# M4KN register map
File version: 0.1
Registers are 32-bit, read-write, reset 0x0 unless marked. A register's access mark holds for its fields unless they carry their own. Offsets are from the block's base; [hi:lo] are bit positions; {n}, {i} and the like mark numbered series.

## PK — Port K
Base 0x400E0900
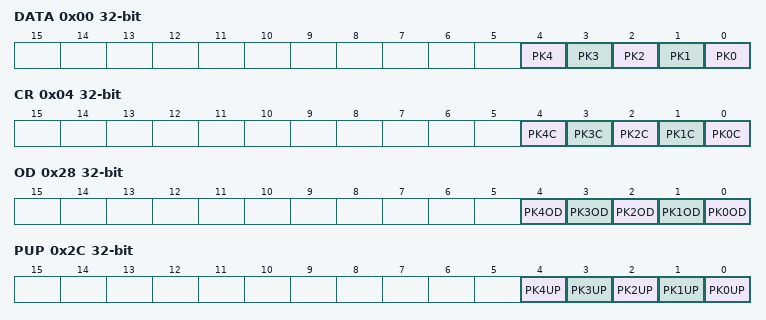
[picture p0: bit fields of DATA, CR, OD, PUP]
0x00 DATA — Port K Data Register
  [n] PK{n} (n=0..4)
0x04 CR — Port K Output Control Register
  [n] PK{n}C (n=0..4)
0x28 OD — Port K Open Drain Control Register
  [n] PK{n}OD (n=0..4)
0x2C PUP — Port K Pull-up Control Register
  [n] PK{n}UP (n=0..4)
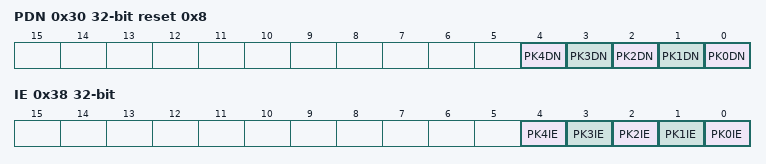
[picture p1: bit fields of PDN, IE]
0x30 PDN reset 0x8 — Port K Pull-down Control Register
  [n] PK{n}DN (n=0..4)
0x38 IE — Port K Input Control Register
  [n] PK{n}IE (n=0..4)

## PL — Port L
Base 0x400E0A00
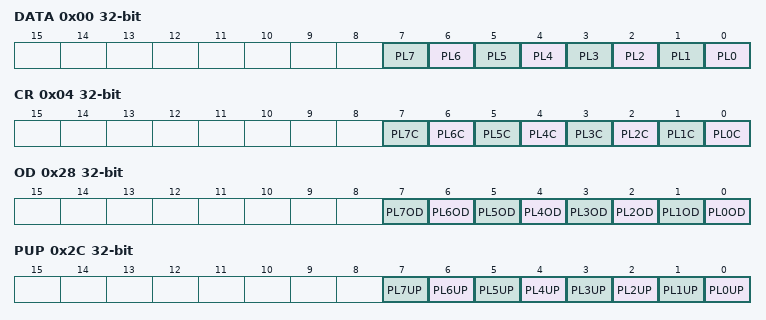
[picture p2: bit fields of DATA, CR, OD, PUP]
0x00 DATA — Port L Data Register
  [n] PL{n} (n=0..7)
0x04 CR — Port L Output Control Register
  [n] PL{n}C (n=0..7)
0x28 OD — Port L Open Drain Control Register
  [n] PL{n}OD (n=0..7)
0x2C PUP — Port L Pull-up Control Register
  [n] PL{n}UP (n=0..7)
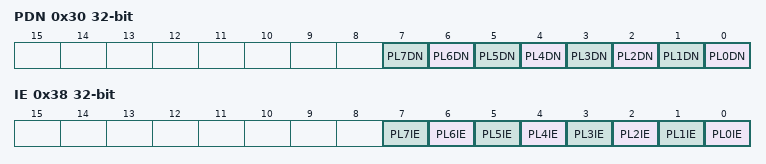
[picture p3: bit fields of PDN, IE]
0x30 PDN — Port L Pull-down Control Register
  [n] PL{n}DN (n=0..7)
0x38 IE — Port L Input Control Register
  [n] PL{n}IE (n=0..7)

## PM — Port M
Base 0x400E0B00
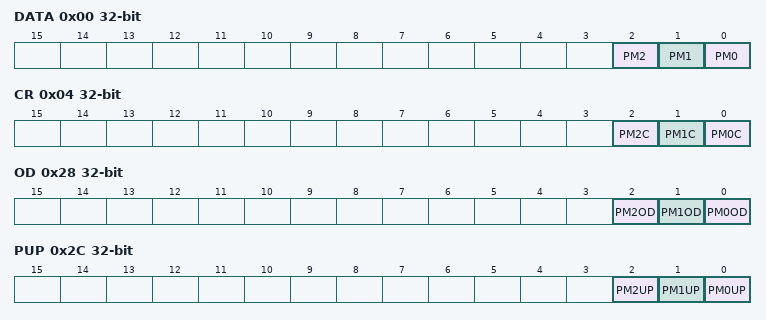
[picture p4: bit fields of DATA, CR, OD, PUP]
0x00 DATA — Port M Data Register
  [2] PM2, [1] PM1, [0] PM0
0x04 CR — Port M Output Control Register
  [2] PM2C, [1] PM1C, [0] PM0C
0x28 OD — Port M Open Drain Control Register
  [2] PM2OD, [1] PM1OD, [0] PM0OD
0x2C PUP — Port M Pull-up Control Register
  [2] PM2UP, [1] PM1UP, [0] PM0UP
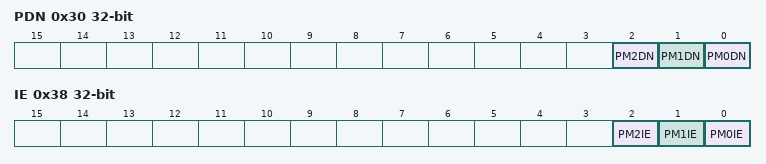
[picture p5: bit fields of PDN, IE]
0x30 PDN — Port M Pull-down Control Register
  [2] PM2DN, [1] PM1DN, [0] PM0DN
0x38 IE — Port M Input Control Register
  [2] PM2IE, [1] PM1IE, [0] PM0IE

## PN — Port N
Base 0x400E0C00
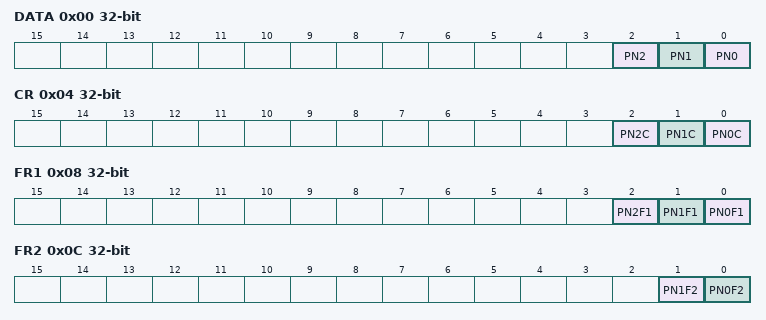
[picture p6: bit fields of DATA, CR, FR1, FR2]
0x00 DATA — Port N Data Register
  [2] PN2, [1] PN1, [0] PN0
0x04 CR — Port N Output Control Register
  [2] PN2C, [1] PN1C, [0] PN0C
0x08 FR1 — Port N Function Register 1
  [2] PN2F1, [1] PN1F1, [0] PN0F1
0x0C FR2 — Port N Function Register 2
  [1] PN1F2, [0] PN0F2
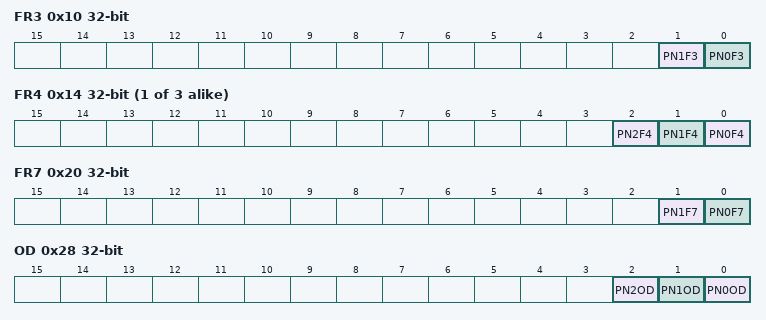
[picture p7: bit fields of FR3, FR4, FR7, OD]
0x10 FR3 — Port N Function Register 3
  [1] PN1F3, [0] PN0F3
{0x4+4i} FR{i} (i=4..6) — Port N Function Register {i}
  [2] PN2F{i}, [1] PN1F{i}, [0] PN0F{i}
0x20 FR7 — Port N Function Register 7
  [1] PN1F7, [0] PN0F7
0x28 OD — Port N Opend Drain Control Register
  [2] PN2OD, [1] PN1OD, [0] PN0OD
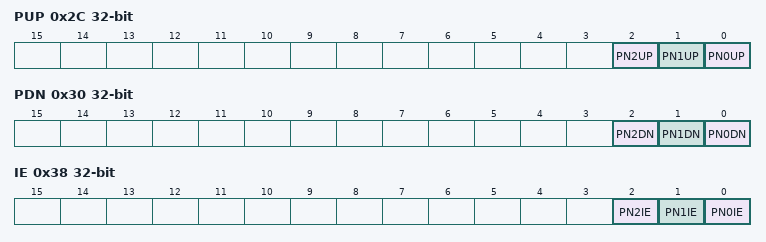
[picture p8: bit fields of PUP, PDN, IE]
0x2C PUP — Port N Pull-up Control Register
  [2] PN2UP, [1] PN1UP, [0] PN0UP
0x30 PDN — Port N Pull-down Control Register
  [2] PN2DN, [1] PN1DN, [0] PN0DN
0x38 IE — Port N Input Control Register
  [2] PN2IE, [1] PN1IE, [0] PN0IE

## PU — Port U
Base 0x400E1000
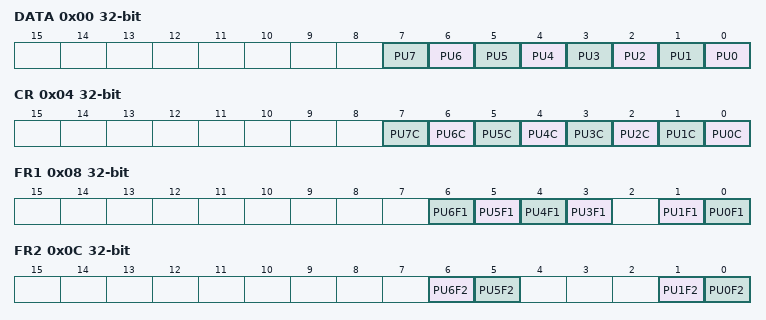
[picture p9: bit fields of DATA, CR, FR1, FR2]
0x00 DATA — Port U Data Register
  [n] PU{n} (n=0..7)
0x04 CR — Port U Output Control Register
  [n] PU{n}C (n=0..7)
0x08 FR1 — Port U Function Register 1
  [n] PU{n}F1 (n=3..6), [1] PU1F1, [0] PU0F1
0x0C FR2 — Port U Function Register 2
  [6] PU6F2, [5] PU5F2, [1] PU1F2, [0] PU0F2
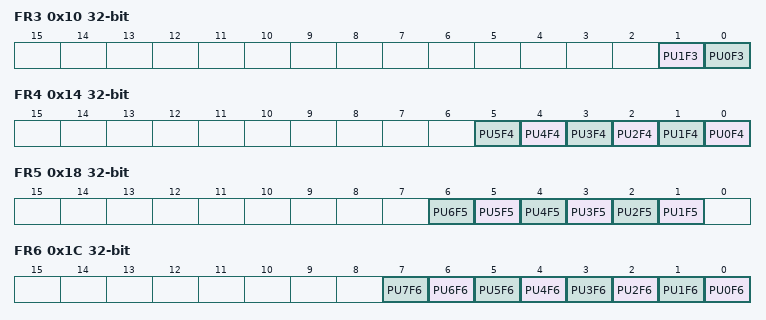
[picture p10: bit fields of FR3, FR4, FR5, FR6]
0x10 FR3 — Port U Function Register 3
  [1] PU1F3, [0] PU0F3
0x14 FR4 — Port U Function Register 4
  [n] PU{n}F4 (n=0..5)
0x18 FR5 — Port U Function Register 5
  [n] PU{n}F5 (n=1..6)
0x1C FR6 — Port U Function Register 6
  [n] PU{n}F6 (n=0..7)
0x20 FR7 — Port U Function Register 7
  [7] PU7F7
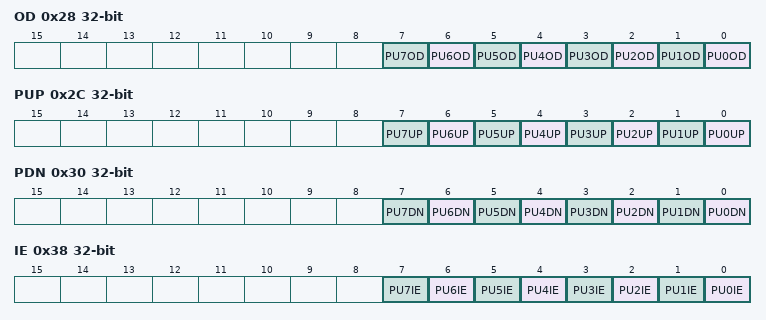
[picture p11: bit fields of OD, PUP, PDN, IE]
0x28 OD — Port U Open Drain Control Register
  [n] PU{n}OD (n=0..7)
0x2C PUP — Port U Pull-up Control Register
  [n] PU{n}UP (n=0..7)
0x30 PDN — Port U Pull-down Control Register
  [n] PU{n}DN (n=0..7)
0x38 IE — Port U Input Control Register
  [n] PU{n}IE (n=0..7)

## PV — Port V
Base 0x400E1100
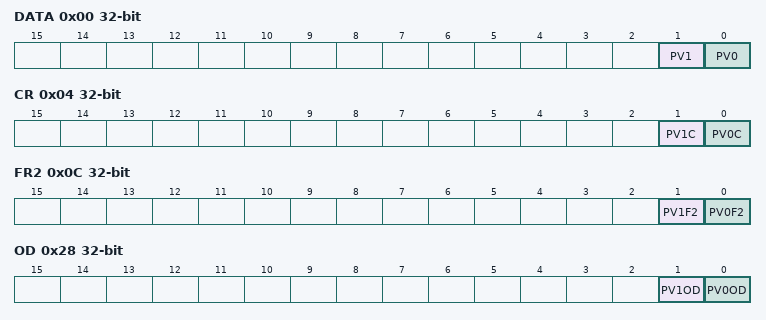
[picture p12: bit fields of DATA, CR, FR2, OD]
0x00 DATA — Port V Data Register
  [1] PV1, [0] PV0
0x04 CR — Port V OutPut Control Register
  [1] PV1C, [0] PV0C
0x08 FR1 — Port V Function Register 1
  [1] PV1F1
0x0C FR2 — Port V Function Register 2
  [1] PV1F2, [0] PV0F2
0x14 FR4 — Port V Function Register 4
  [0] PV0F4
0x28 OD — Port V Open Drain Control Register
  [1] PV1OD, [0] PV0OD
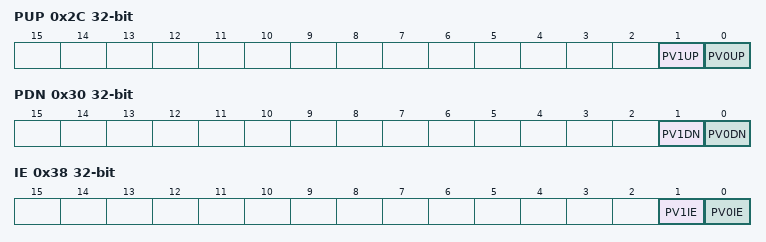
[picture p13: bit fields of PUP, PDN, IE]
0x2C PUP — Port V Pull-up Control Register
  [1] PV1UP, [0] PV0UP
0x30 PDN — Port V Pull-down Control Register
  [1] PV1DN, [0] PV0DN
0x38 IE — Port V InPut Control Register
  [1] PV1IE, [0] PV0IE

## TRM — Trimming Circuit (TRM)
Base 0x400E3100
0x00 OSCPRO — Protection Register
  [7:0] PROTECT
0x04 OSCEN — TRM Enable Register
  [0] TRIMEN
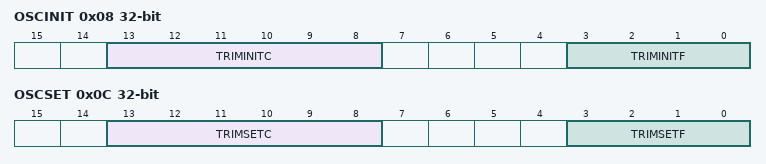
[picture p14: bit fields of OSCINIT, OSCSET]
0x08 OSCINIT ro (reset mask 0xFFFFC0F0) — TRM Initial Trimming Level Monitor Register
  [13:8] TRIMINITC, [3:0] TRIMINITF
0x0C OSCSET — TRM Trimming Level Setting Register
  [13:8] TRIMSETC, [3:0] TRIMSETF
